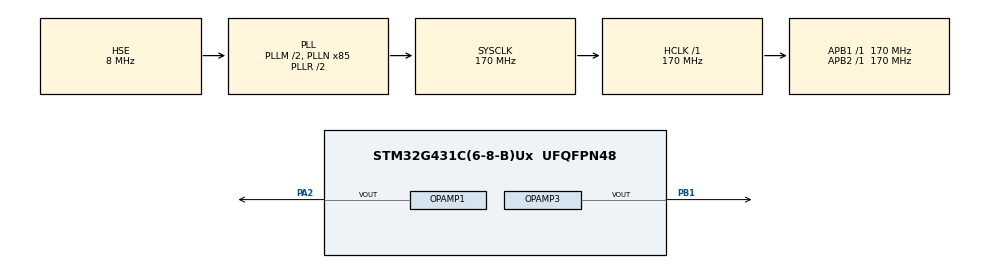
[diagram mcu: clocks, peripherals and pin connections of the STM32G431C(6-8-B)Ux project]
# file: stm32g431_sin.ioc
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DAC3.DAC_Channel-DAC_OUT2_Int=DAC_CHANNEL_2
Dma.DAC3_CH1.0.Direction=DMA_MEMORY_TO_PERIPH
Dma.DAC3_CH1.0.EventEnable=DISABLE
Dma.DAC3_CH1.0.Instance=DMA1_Channel1
Dma.DAC3_CH1.0.MemDataAlignment=DMA_MDATAALIGN_HALFWORD
Dma.DAC3_CH1.0.MemInc=DMA_MINC_ENABLE
Dma.DAC3_CH1.0.Mode=DMA_CIRCULAR
Dma.DAC3_CH1.0.PeriphDataAlignment=DMA_PDATAALIGN_HALFWORD
Dma.DAC3_CH1.0.PeriphInc=DMA_PINC_DISABLE
Dma.DAC3_CH1.0.Polarity=HAL_DMAMUX_REQ_GEN_RISING
Dma.DAC3_CH1.0.Priority=DMA_PRIORITY_HIGH
Dma.DAC3_CH1.0.RequestNumber=1
Dma.DAC3_CH1.0.SignalID=NONE
Dma.DAC3_CH1.0.SyncEnable=DISABLE
Dma.DAC3_CH1.0.SyncPolarity=HAL_DMAMUX_SYNC_NO_EVENT
Dma.DAC3_CH1.0.SyncRequestNumber=1
Dma.DAC3_CH1.0.SyncSignalID=NONE
Dma.Request0=DAC3_CH1
Mcu.Family=STM32G4
Mcu.Name=STM32G431C(6-8-B)Ux
Mcu.Package=UFQFPN48
NVIC.DMA1_Channel1_IRQn=true\:0\:0\:false\:false\:true\:false\:true\:true
NVIC.PriorityGroup=NVIC_PRIORITYGROUP_4
OPAMP1.PowerMode=OPAMP_POWERMODE_HIGHSPEED
PA13.Mode=Serial_Wire
PA13.Signal=SYS_JTMS-SWDIO
PA14.Mode=Serial_Wire
PA14.Signal=SYS_JTCK-SWCLK
PA2.Mode=Follower-DAC_OUT2-INP
PA2.Signal=OPAMP1_VOUT
PB1.Mode=Follower-DAC_OUT2-INP
PB1.Signal=OPAMP3_VOUT
PC14-OSC32_IN.Mode=LSE-External-Oscillator
PC14-OSC32_IN.Signal=RCC_OSC32_IN
PC15-OSC32_OUT.Mode=LSE-External-Oscillator
PC15-OSC32_OUT.Signal=RCC_OSC32_OUT
PF0-OSC_IN.Mode=HSE-External-Oscillator
PF0-OSC_IN.Signal=RCC_OSC_IN
PF1-OSC_OUT.Mode=HSE-External-Oscillator
PF1-OSC_OUT.Signal=RCC_OSC_OUT
ProjectManager.HeapSize=0x200
ProjectManager.StackSize=0x400
ProjectManager.TargetToolchain=CMake
RCC.ADC12Freq_Value=170000000
RCC.AHBFreq_Value=170000000
RCC.APB1Freq_Value=170000000
RCC.APB1TimFreq_Value=170000000
RCC.APB2Freq_Value=170000000
RCC.APB2TimFreq_Value=170000000
RCC.CortexFreq_Value=170000000
RCC.EXTERNAL_CLOCK_VALUE=12288000
RCC.HCLKFreq_Value=170000000
RCC.HSE_VALUE=8000000
RCC.HSI48_VALUE=48000000
RCC.HSI_VALUE=16000000
RCC.PLLM=RCC_PLLM_DIV2
RCC.PLLN=85
RCC.PLLSourceVirtual=RCC_PLLSOURCE_HSE
RCC.SYSCLKFreq_VALUE=170000000
RCC.SYSCLKSource=RCC_SYSCLKSOURCE_PLLCLK
RCC.USBFreq_Value=170000000
RCC.VCOOutputFreq_Value=340000000
VP_DAC3_VS_DACI1.Mode=DAC_OUT1_Int
VP_DAC3_VS_DACI2.Mode=DAC_OUT2_Int
VP_SYS_VS_DBSignals.Mode=DisableDeadBatterySignals
VP_TIM1_VS_ClockSourceINT.Mode=Internal
TIM1.Period=249
board=custom

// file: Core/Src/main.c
/* USER CODE BEGIN Header */
/**
  ******************************************************************************
  * @file           : main.c
  * @brief          : Main program body
  ******************************************************************************
  * @attention
  *
  * Copyright (c) 2026 STMicroelectronics.
  * All rights reserved.
  *
  * This software is licensed under terms that can be found in the LICENSE file
  * in the root directory of this software component.
  * If no LICENSE file comes with this software, it is provided AS-IS.
  *
  ******************************************************************************
  */
/* USER CODE END Header */
#include "main.h"

/* USER CODE BEGIN Includes */
#include <math.h>

/* USER CODE END Includes */

DAC_HandleTypeDef hdac3;
DMA_HandleTypeDef hdma_dac3_ch1;

OPAMP_HandleTypeDef hopamp1;
OPAMP_HandleTypeDef hopamp3;

TIM_HandleTypeDef htim1;

/* USER CODE BEGIN PV */
/* DAC3 -> OPAMP1 unity-gain buffer -> PA2 output. */
#define SINE_FREQUENCY_HZ       10000U
#define SINE_TABLE_LENGTH       68U
#define DAC_REFERENCE_MV        3300.0f
#define SINE_OFFSET_MV          2500.0f
#define SINE_AMPLITUDE_MV       75.0f
#define DAC_FULL_SCALE          4095.0f
#define PI_F                    3.14159265358979323846f
#define DAC_REFERENCE_2V5_CODE  3102U  /* 2.5 V at VDDA = 3.3 V */

uint16_t sine_table[SINE_TABLE_LENGTH];
volatile uint32_t sine_index = 1U;

/* USER CODE END PV */

void SystemClock_Config(void);
static void MX_GPIO_Init(void);
static void MX_DMA_Init(void);
static void MX_DAC3_Init(void);
static void MX_OPAMP1_Init(void);
static void MX_TIM1_Init(void);
static void MX_OPAMP3_Init(void);
/* USER CODE BEGIN PFP */
static void SineTable_Init(void);

/* USER CODE END PFP */

/* USER CODE BEGIN 0 */
static void SineTable_Init(void)
{
  for (uint32_t i = 0; i < SINE_TABLE_LENGTH; ++i)
  {
    const float phase = (2.0f * PI_F * (float)i) / (float)SINE_TABLE_LENGTH;
    const float voltage_mv = SINE_OFFSET_MV + SINE_AMPLITUDE_MV * sinf(phase);
    int32_t code = (int32_t)((voltage_mv * DAC_FULL_SCALE / DAC_REFERENCE_MV) + 0.5f);

    if (code < 0)
    {
      code = 0;
    }
    else if (code > (int32_t)DAC_FULL_SCALE)
    {
      code = (int32_t)DAC_FULL_SCALE;
    }

    sine_table[i] = (uint16_t)code;
  }
}

/* USER CODE END 0 */

int main(void)
{

  /* MCU Configuration--------------------------------------------------------*/

  /* Reset of all peripherals, Initializes the Flash interface and the Systick. */
  HAL_Init();

  /* Configure the system clock */
  SystemClock_Config();

  /* Initialize all configured peripherals */
  MX_GPIO_Init();
  MX_DMA_Init();
  MX_DAC3_Init();
  MX_OPAMP1_Init();
  MX_TIM1_Init();
  MX_OPAMP3_Init();
  /* USER CODE BEGIN 2 */
  SineTable_Init();

  if (HAL_OPAMP_Start(&hopamp1) != HAL_OK)
  {
    Error_Handler();
  }

  /* DAC3_CH2 is internally routed to OPAMP3; buffered reference is on PB1. */
  if (HAL_OPAMP_Start(&hopamp3) != HAL_OK)
  {
    Error_Handler();
  }
  if (HAL_DAC_SetValue(&hdac3, DAC_CHANNEL_2, DAC_ALIGN_12B_R,
                       DAC_REFERENCE_2V5_CODE) != HAL_OK)
  {
    Error_Handler();
  }
  if (HAL_DAC_Start(&hdac3, DAC_CHANNEL_2) != HAL_OK)
  {
    Error_Handler();
  }

  if (HAL_DAC_SetValue(&hdac3, DAC_CHANNEL_1, DAC_ALIGN_12B_R,
                       sine_table[0]) != HAL_OK)
  {
    Error_Handler();
  }

  if (HAL_DAC_Start(&hdac3, DAC_CHANNEL_1) != HAL_OK)
  {
    Error_Handler();
  }

  /* 680 kHz / 68 samples = exactly 10 kHz. */
  if (HAL_TIM_Base_Start_IT(&htim1) != HAL_OK)
  {
    Error_Handler();
  }

  /* USER CODE END 2 */

  /* Infinite loop */
  while (1)
  {

  }
}

void SystemClock_Config(void)
{
  RCC_OscInitTypeDef RCC_OscInitStruct = {0};
  RCC_ClkInitTypeDef RCC_ClkInitStruct = {0};

  /** Configure the main internal regulator output voltage
  */
  HAL_PWREx_ControlVoltageScaling(PWR_REGULATOR_VOLTAGE_SCALE1_BOOST);

  /** Initializes the RCC Oscillators according to the specified parameters
  * in the RCC_OscInitTypeDef structure.
  */
  RCC_OscInitStruct.OscillatorType = RCC_OSCILLATORTYPE_HSE;
  RCC_OscInitStruct.HSEState = RCC_HSE_ON;
  RCC_OscInitStruct.PLL.PLLState = RCC_PLL_ON;
  RCC_OscInitStruct.PLL.PLLSource = RCC_PLLSOURCE_HSE;
  RCC_OscInitStruct.PLL.PLLM = RCC_PLLM_DIV2;
  RCC_OscInitStruct.PLL.PLLN = 85;
  RCC_OscInitStruct.PLL.PLLP = RCC_PLLP_DIV2;
  RCC_OscInitStruct.PLL.PLLQ = RCC_PLLQ_DIV2;
  RCC_OscInitStruct.PLL.PLLR = RCC_PLLR_DIV2;
  if (HAL_RCC_OscConfig(&RCC_OscInitStruct) != HAL_OK)
  {
    Error_Handler();
  }

  /** Initializes the CPU, AHB and APB buses clocks
  */
  RCC_ClkInitStruct.ClockType = RCC_CLOCKTYPE_HCLK|RCC_CLOCKTYPE_SYSCLK
                              |RCC_CLOCKTYPE_PCLK1|RCC_CLOCKTYPE_PCLK2;
  RCC_ClkInitStruct.SYSCLKSource = RCC_SYSCLKSOURCE_PLLCLK;
  RCC_ClkInitStruct.AHBCLKDivider = RCC_SYSCLK_DIV1;
  RCC_ClkInitStruct.APB1CLKDivider = RCC_HCLK_DIV1;
  RCC_ClkInitStruct.APB2CLKDivider = RCC_HCLK_DIV1;

  if (HAL_RCC_ClockConfig(&RCC_ClkInitStruct, FLASH_LATENCY_4) != HAL_OK)
  {
    Error_Handler();
  }
}

static void MX_DAC3_Init(void)
{

  DAC_ChannelConfTypeDef sConfig = {0};

  /** DAC Initialization
  */
  hdac3.Instance = DAC3;
  if (HAL_DAC_Init(&hdac3) != HAL_OK)
  {
    Error_Handler();
  }

  /** DAC channel OUT1 config
  */
  sConfig.DAC_HighFrequency = DAC_HIGH_FREQUENCY_INTERFACE_MODE_AUTOMATIC;
  sConfig.DAC_DMADoubleDataMode = DISABLE;
  sConfig.DAC_SignedFormat = DISABLE;
  sConfig.DAC_SampleAndHold = DAC_SAMPLEANDHOLD_DISABLE;
  sConfig.DAC_Trigger = DAC_TRIGGER_NONE;
  sConfig.DAC_Trigger2 = DAC_TRIGGER_NONE;
  sConfig.DAC_OutputBuffer = DAC_OUTPUTBUFFER_DISABLE;
  sConfig.DAC_ConnectOnChipPeripheral = DAC_CHIPCONNECT_INTERNAL;
  sConfig.DAC_UserTrimming = DAC_TRIMMING_FACTORY;
  if (HAL_DAC_ConfigChannel(&hdac3, &sConfig, DAC_CHANNEL_1) != HAL_OK)
  {
    Error_Handler();
  }

  /** DAC channel OUT2 config
  */
  if (HAL_DAC_ConfigChannel(&hdac3, &sConfig, DAC_CHANNEL_2) != HAL_OK)
  {
    Error_Handler();
  }

}

static void MX_OPAMP1_Init(void)
{

  hopamp1.Instance = OPAMP1;
  hopamp1.Init.PowerMode = OPAMP_POWERMODE_HIGHSPEED;
  hopamp1.Init.Mode = OPAMP_FOLLOWER_MODE;
  hopamp1.Init.NonInvertingInput = OPAMP_NONINVERTINGINPUT_DAC;
  hopamp1.Init.InternalOutput = DISABLE;
  hopamp1.Init.TimerControlledMuxmode = OPAMP_TIMERCONTROLLEDMUXMODE_DISABLE;
  hopamp1.Init.UserTrimming = OPAMP_TRIMMING_FACTORY;
  if (HAL_OPAMP_Init(&hopamp1) != HAL_OK)
  {
    Error_Handler();
  }

}

static void MX_OPAMP3_Init(void)
{

  hopamp3.Instance = OPAMP3;
  hopamp3.Init.PowerMode = OPAMP_POWERMODE_NORMALSPEED;
  hopamp3.Init.Mode = OPAMP_FOLLOWER_MODE;
  hopamp3.Init.NonInvertingInput = OPAMP_NONINVERTINGINPUT_DAC;
  hopamp3.Init.InternalOutput = DISABLE;
  hopamp3.Init.TimerControlledMuxmode = OPAMP_TIMERCONTROLLEDMUXMODE_DISABLE;
  hopamp3.Init.UserTrimming = OPAMP_TRIMMING_FACTORY;
  if (HAL_OPAMP_Init(&hopamp3) != HAL_OK)
  {
    Error_Handler();
  }

}

static void MX_TIM1_Init(void)
{

  TIM_ClockConfigTypeDef sClockSourceConfig = {0};
  TIM_MasterConfigTypeDef sMasterConfig = {0};

  htim1.Instance = TIM1;
  htim1.Init.Prescaler = 0;
  htim1.Init.CounterMode = TIM_COUNTERMODE_UP;
  /* 170 MHz / (249 + 1) / 68 samples = exactly 10 kHz. */
  htim1.Init.Period = 249;
  htim1.Init.ClockDivision = TIM_CLOCKDIVISION_DIV1;
  htim1.Init.RepetitionCounter = 0;
  htim1.Init.AutoReloadPreload = TIM_AUTORELOAD_PRELOAD_DISABLE;
  if (HAL_TIM_Base_Init(&htim1) != HAL_OK)
  {
    Error_Handler();
  }
  sClockSourceConfig.ClockSource = TIM_CLOCKSOURCE_INTERNAL;
  if (HAL_TIM_ConfigClockSource(&htim1, &sClockSourceConfig) != HAL_OK)
  {
    Error_Handler();
  }
  sMasterConfig.MasterOutputTrigger = TIM_TRGO_RESET;
  sMasterConfig.MasterOutputTrigger2 = TIM_TRGO2_RESET;
  sMasterConfig.MasterSlaveMode = TIM_MASTERSLAVEMODE_DISABLE;
  if (HAL_TIMEx_MasterConfigSynchronization(&htim1, &sMasterConfig) != HAL_OK)
  {
    Error_Handler();
  }

}

static void MX_DMA_Init(void)
{

  /* DMA controller clock enable */
  __HAL_RCC_DMAMUX1_CLK_ENABLE();
  __HAL_RCC_DMA1_CLK_ENABLE();

  /* DMA interrupt init */
  /* DMA1_Channel1_IRQn interrupt configuration */
  HAL_NVIC_SetPriority(DMA1_Channel1_IRQn, 0, 0);
  HAL_NVIC_EnableIRQ(DMA1_Channel1_IRQn);

}

static void MX_GPIO_Init(void)
{

  /* GPIO Ports Clock Enable */
  __HAL_RCC_GPIOC_CLK_ENABLE();
  __HAL_RCC_GPIOF_CLK_ENABLE();
  __HAL_RCC_GPIOA_CLK_ENABLE();
  __HAL_RCC_GPIOB_CLK_ENABLE();

}

void Error_Handler(void)
{
  __disable_irq();
  while (1)
  {
  }
}
